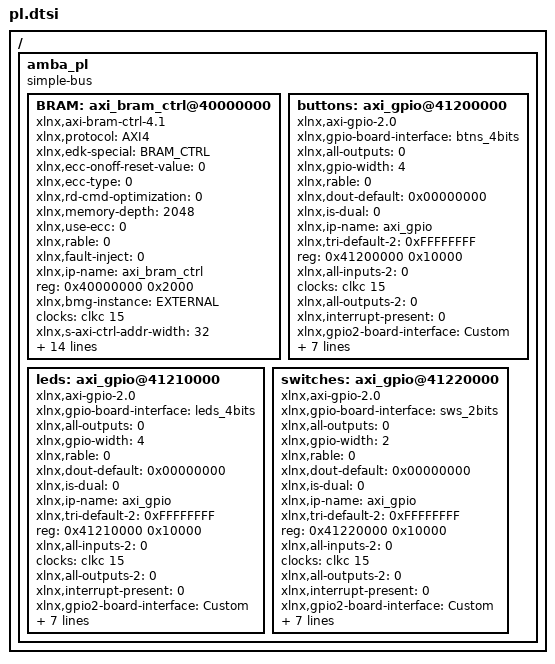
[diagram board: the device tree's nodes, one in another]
/ {
	amba_pl: amba_pl {
		ranges;
		compatible = "simple-bus";
		#address-cells = <1>;
		#size-cells = <1>;
		BRAM: axi_bram_ctrl@40000000 {
			xlnx,protocol = "AXI4";
			xlnx,edk-special = "BRAM_CTRL";
			compatible = "xlnx,axi-bram-ctrl-4.1";
			xlnx,ecc-onoff-reset-value = <0>;
			xlnx,ecc-type = <0>;
			xlnx,rd-cmd-optimization = <0>;
			xlnx,memory-depth = <2048>;
			xlnx,use-ecc = <0>;
			xlnx,rable = <0>;
			xlnx,fault-inject = <0>;
			xlnx,ip-name = "axi_bram_ctrl";
			reg = <0x40000000 0x2000>;
			xlnx,bmg-instance = "EXTERNAL";
			clocks = <&clkc 15>;
			xlnx,s-axi-ctrl-addr-width = <32>;
			xlnx,read-latency = <1>;
			xlnx,s-axi-supports-narrow-burst = <0>;
			xlnx,id-width = <0>;
			xlnx,supports-narrow-burst = <0>;
			xlnx,single-port-bram = <0>;
			xlnx,ecc = <0>;
			xlnx,edk-iptype = "PERIPHERAL";
			status = "okay";
			clock-names = "s_axi_aclk";
			xlnx,bram-addr-width = <11>;
			xlnx,bram-inst-mode = "EXTERNAL";
			xlnx,data-width = <32>;
			xlnx,s-axi-ctrl-data-width = <32>;
			xlnx,s-axi-id-width = <1>;
			xlnx,mem-depth = <2048>;
			xlnx,name = "BRAM";
		};
		buttons: axi_gpio@41200000 {
			xlnx,gpio-board-interface = "btns_4bits";
			compatible = "xlnx,axi-gpio-2.0" , "xlnx,xps-gpio-1.00.a";
			xlnx,all-outputs = <0>;
			xlnx,gpio-width = <4>;
			xlnx,rable = <0>;
			xlnx,dout-default = <0x00000000>;
			xlnx,is-dual = <0>;
			xlnx,ip-name = "axi_gpio";
			xlnx,tri-default-2 = <0xFFFFFFFF>;
			reg = <0x41200000 0x10000>;
			xlnx,all-inputs-2 = <0>;
			clocks = <&clkc 15>;
			xlnx,all-outputs-2 = <0>;
			xlnx,interrupt-present = <0>;
			xlnx,gpio2-board-interface = "Custom";
			xlnx,edk-iptype = "PERIPHERAL";
			xlnx,dout-default-2 = <0x00000000>;
			xlnx,gpio2-width = <32>;
			status = "okay";
			clock-names = "s_axi_aclk";
			xlnx,use-board-flow;
			xlnx,tri-default = <0xFFFFFFFF>;
			xlnx,name = "buttons";
			xlnx,all-inputs = <1>;
		};
		leds: axi_gpio@41210000 {
			xlnx,gpio-board-interface = "leds_4bits";
			compatible = "xlnx,axi-gpio-2.0" , "xlnx,xps-gpio-1.00.a";
			xlnx,all-outputs = <0>;
			xlnx,gpio-width = <4>;
			xlnx,rable = <0>;
			xlnx,dout-default = <0x00000000>;
			xlnx,is-dual = <0>;
			xlnx,ip-name = "axi_gpio";
			xlnx,tri-default-2 = <0xFFFFFFFF>;
			reg = <0x41210000 0x10000>;
			xlnx,all-inputs-2 = <0>;
			clocks = <&clkc 15>;
			xlnx,all-outputs-2 = <0>;
			xlnx,interrupt-present = <0>;
			xlnx,gpio2-board-interface = "Custom";
			xlnx,edk-iptype = "PERIPHERAL";
			xlnx,dout-default-2 = <0x00000000>;
			xlnx,gpio2-width = <32>;
			status = "okay";
			clock-names = "s_axi_aclk";
			xlnx,use-board-flow;
			xlnx,tri-default = <0xFFFFFFFF>;
			xlnx,name = "leds";
			xlnx,all-inputs = <0>;
		};
		switches: axi_gpio@41220000 {
			xlnx,gpio-board-interface = "sws_2bits";
			compatible = "xlnx,axi-gpio-2.0" , "xlnx,xps-gpio-1.00.a";
			xlnx,all-outputs = <0>;
			xlnx,gpio-width = <2>;
			xlnx,rable = <0>;
			xlnx,dout-default = <0x00000000>;
			xlnx,is-dual = <0>;
			xlnx,ip-name = "axi_gpio";
			xlnx,tri-default-2 = <0xFFFFFFFF>;
			reg = <0x41220000 0x10000>;
			xlnx,all-inputs-2 = <0>;
			clocks = <&clkc 15>;
			xlnx,all-outputs-2 = <0>;
			xlnx,interrupt-present = <0>;
			xlnx,gpio2-board-interface = "Custom";
			xlnx,edk-iptype = "PERIPHERAL";
			xlnx,dout-default-2 = <0x00000000>;
			xlnx,gpio2-width = <32>;
			status = "okay";
			clock-names = "s_axi_aclk";
			xlnx,use-board-flow;
			xlnx,tri-default = <0xFFFFFFFF>;
			xlnx,name = "switches";
			xlnx,all-inputs = <1>;
		};
	};
};
